# CORE_CM2 register map
Vendor: Texas Instruments
Peripheral module from a debugger description file (folder omap4460).
Registers are 32-bit, access not given, reset 0x30001 unless marked. A register's access mark holds for its fields unless they carry their own. Offsets are as the file gives them; lines under a group give offsets from that group; [hi:lo] are bit positions; {n}, {i} and the like mark numbered series; 'fields as' and 'values as' point back to an identical list; <NAME> marks a mode.

## CORE_CM2
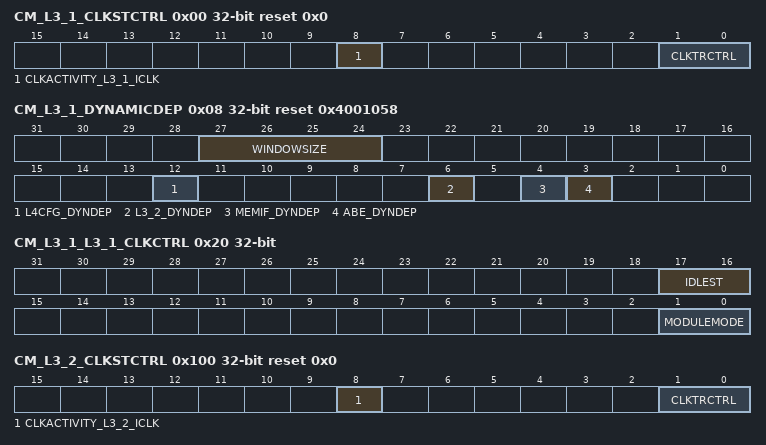
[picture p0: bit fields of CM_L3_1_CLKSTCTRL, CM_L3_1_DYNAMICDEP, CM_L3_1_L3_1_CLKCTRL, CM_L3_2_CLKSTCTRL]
0x00 CM_L3_1_CLKSTCTRL access per field reset 0x0 — This register enables the domain power state transition. It controls the hardware supervised domain power state transition between ON-ACTIVE and ON-INACTIVE states. It also holds 1 status bit per clock input of the domain.
  [8] CLKACTIVITY_L3_1_ICLK ro — This field indicates the state of the L3_1_ICLK clock in the domain. [warm reset insensitive]
    0=CLKACTIVITY_L3_1_ICLK_0_r (Corresponding clock is definitely gated); 1=CLKACTIVITY_L3_1_ICLK_1_r (Corresponding clock is running or gating/ungating transition is ongoing)
  [1:0] CLKTRCTRL rw — Controls the clock state transition of the L3_1 clock domain.
    0=NO_SLEEP: Sleep transition cannot be initiated. Wakeup transition may however occur.; 1=CLKTRCTRL_1_r (Reserved); 2=CLKTRCTRL_2_r (Reserved); 3=HW_AUTO: Automatic transition is enabled. Sleep and wakeup transition are based upon hardware conditions.
0x08 CM_L3_1_DYNAMICDEP reset 0x4001058 — This register controls the dynamic domain depedencies from L3_1 domain towards 'target' domains. It is relevant only for domain having INTRCONN master port(s).
  [27:24] WINDOWSIZE rw — Size of sliding window used to monitor INTRCONN interface activity for determination of auto-sleep feature. Time unit defined byCM_DYN_DEP_PRESCAL register.
  [12] L4CFG_DYNDEP — Dynamic dependency towards L4CFG clock domain (access R Rreturns1s)
    1=L4CFG_DYNDEP_1_r (Dependency is enabled)
  [6] L3_2_DYNDEP — Dynamic dependency towards L3_2 clock domain (access R Rreturns1s)
    1=L3_2_DYNDEP_1_r (Dependency is enabled)
  [4] MEMIF_DYNDEP — Dynamic dependency towards MEMIF clock domain (access R Rreturns1s)
    1=MEMIF_DYNDEP_1_r (Dependency is enabled)
  [3] ABE_DYNDEP — Dynamic dependency towards ABE clock domain (access R Rreturns1s)
    1=ABE_DYNDEP_1_r (Dependency is enabled)
0x20 CM_L3_1_L3_1_CLKCTRL — This register manages the L3_1 clocks.
  [17:16] IDLEST ro — Module idle status. [warm reset insensitive]
    0=IDLEST_0_r (Module is fully functional, including INTRCONN); 1=IDLEST_1_r (Module is performing transition: wakeup, or sleep, or sleep abortion); 2=IDLEST_2_r (Module is in idle mode (only INTRCONN part). It is functional if using separate functional clock); 3=IDLEST_3_r (Module is disabled and cannot be accessed)
  [1:0] MODULEMODE — Control the way mandatory clocks are managed. (access R Rreturns)
    1=MODULEMODE_1_r (Module is managed automatically by hardware according to clock domain transition. A clock domain sleep transition put module into idle. A wakeup domain transition put it back into function. If CLKTRCTRL=3, any INTRCONN access to module is always granted. Module clocks may be gated according to the clock domain state.)
0x100 CM_L3_2_CLKSTCTRL access per field reset 0x0 — This register enables the domain power state transition. It controls the hardware supervised domain power state transition between ON-ACTIVE and ON-INACTIVE states. It also holds 1 status bit per clock input of the domain.
  [8] CLKACTIVITY_L3_2_ICLK ro — This field indicates the state of the L3_2_ICLK clock in the domain. [warm reset insensitive]
    0=CLKACTIVITY_L3_2_ICLK_0_r (Corresponding clock is definitely gated); 1=CLKACTIVITY_L3_2_ICLK_1_r (Corresponding clock is running or gating/ungating transition is ongoing)
  [1:0] CLKTRCTRL rw — Controls the clock state transition of the L3_2 clock domain.
    values as CM_L3_1_CLKSTCTRL.CLKTRCTRL
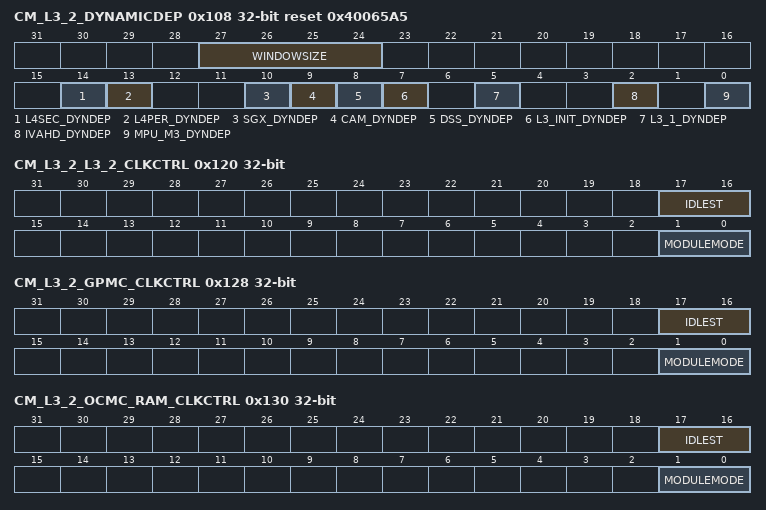
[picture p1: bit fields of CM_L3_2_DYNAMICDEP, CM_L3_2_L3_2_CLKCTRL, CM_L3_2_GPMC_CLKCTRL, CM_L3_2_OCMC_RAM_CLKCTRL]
0x108 CM_L3_2_DYNAMICDEP reset 0x40065A5 — This register controls the dynamic domain dependencies from L3_2 domain towards 'target' domains. It is relevant only for domain having INTERCONN master port(s).
  [27:24] WINDOWSIZE rw — Size of sliding window used to monitor INTRCONN interface activity for determination of auto-sleep feature. Time unit defined byCM_DYN_DEP_PRESCAL register.
  [14] L4SEC_DYNDEP ro — Dynamic dependency towards L4SEC clock domain
    1=L4SEC_DYNDEP_1_r (Dependency is enabled)
  [13] L4PER_DYNDEP — Dynamic dependency towards L4PER clock domain (access R Rreturns1s)
    1=L4PER_DYNDEP_1_r (Dependency is enabled)
  [10] SGX_DYNDEP — Dynamic dependency towards SGX clock domain (access R Rreturns1s)
    1=SGX_DYNDEP_1_r (Dependency is enabled)
  [9] CAM_DYNDEP ro — Dynamic dependency towards ISS clock domain
    0=CAM_DYNDEP_0_r (Dependency is disabled)
  [8] DSS_DYNDEP — Dynamic dependency towards DSS clock domain (access R Rreturns1s)
    1=DSS_DYNDEP_1_r (Dependency is enabled)
  [7] L3_INIT_DYNDEP — Dynamic dependency towards L3INIT clock domain (access R Rreturns1s)
    1=L3_INIT_DYNDEP_1_r (Dependency is enabled)
  [5] L3_1_DYNDEP — Dynamic dependency towards L3_1 clock domain (access R Rreturns1s)
    1=L3_1_DYNDEP_1_r (Dependency is enabled)
  [2] IVAHD_DYNDEP — Dynamic dependency towards IVAHD clock domain (access R Rreturns1s)
    1=IVAHD_DYNDEP_1_r (Dependency is enabled)
  [0] MPU_M3_DYNDEP — Dynamic dependency towards CORTEXM3 clock domain (access R Rreturns1s)
    1=MPU_M3_DYNDEP_1_r (Dependency is enabled)
0x120 CM_L3_2_L3_2_CLKCTRL — This register manages the L3_2 clocks.
  fields as CM_L3_1_L3_1_CLKCTRL
0x128 CM_L3_2_GPMC_CLKCTRL access per field — This register manages the GPMC clocks.
  [17:16] IDLEST ro — Module idle status. [warm reset insensitive]
    values as CM_L3_1_L3_1_CLKCTRL.IDLEST
  [1:0] MODULEMODE rw — Control the way mandatory clocks are managed.
    0=Module is temporarily disabled by software. Interconnect access to module are stalled. Can be used to change timing parameter of GPMC module.; 1=Module is managed automatically by hardware according to clock domain transition. A clock domain sleep transition put module into idle. A wakeup domain transition put it back into function. If CLKTRCTRL=3, any INTRCONN access to module is always granted. Module clocks may be gated according to the clock domain state.; 2=MODULEMODE_2_r (Reserved); 3=MODULEMODE_3_r (Reserved)
0x130 CM_L3_2_OCMC_RAM_CLKCTRL — This register manages the OCMC_RAM clocks.
  fields as CM_L3_1_L3_1_CLKCTRL
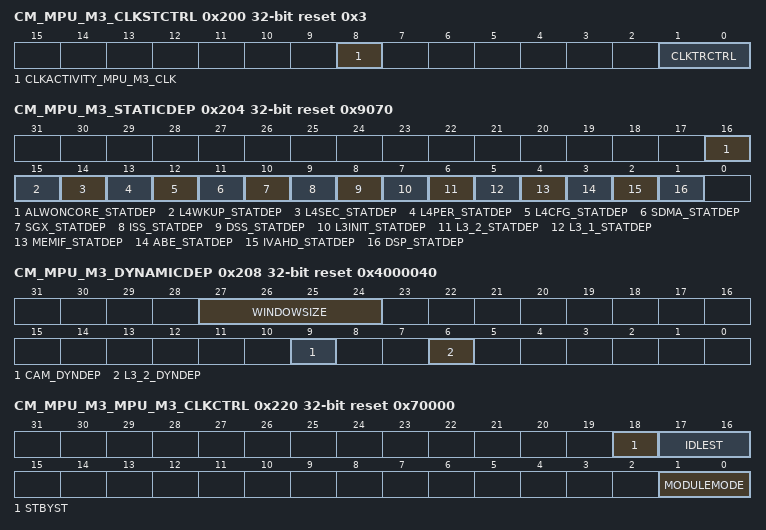
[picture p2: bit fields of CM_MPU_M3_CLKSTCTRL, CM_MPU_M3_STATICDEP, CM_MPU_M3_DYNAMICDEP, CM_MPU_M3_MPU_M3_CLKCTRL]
0x200 CM_MPU_M3_CLKSTCTRL access per field reset 0x3 — This register enables the domain power state transition. It controls the hardware supervised domain power state transition between ON-ACTIVE and ON-INACTIVE states. It also holds 1 status bit per clock input of the domain.
  [8] CLKACTIVITY_MPU_M3_CLK ro — This field indicates the state of the MPU_M3_CLK clock in the domain. [warm reset insensitive]
    0=CLKACTIVITY_MPU_M3_CLK_0_r (Corresponding clock is definitely gated); 1=CLKACTIVITY_MPU_M3_CLK_1_r (Corresponding clock is running or gating/ungating transition is ongoing)
  [1:0] CLKTRCTRL rw — Controls the clock state transition of the MPU_A3 clock domain.
    0=NO_SLEEP: Sleep transition cannot be initiated. Wakeup transition may however occur.; 1=SW_SLEEP: Start a software forced sleep transition on the domain; 2=SW_WKUP: Start a software forced wake-up transition on the domain; 3=HW_AUTO: Automatic transition is enabled. Sleep and wakeup transition are based upon hardware conditions.
0x204 CM_MPU_M3_STATICDEP access per field reset 0x9070 — This register controls the static domain dependencies from MPU_M3 domain towards 'target' domains. It is relevant only for domain having system initiator(s).
  [16] ALWONCORE_STATDEP ro — Static dependency towards ALWONCORE clock domain
    0=ALWONCORE_STATDEP_0_r (Dependency is disabled)
  [15] L4WKUP_STATDEP rw — Static dependency towards L4WKUP clock domain
    0=Dependency is disabled; 1=Dependency is enabled
  [14] L4SEC_STATDEP rw — Static dependency towards L4SEC clock domain
    0=Dependency is disabled; 1=Dependency is enabled
  [13] L4PER_STATDEP rw — Static dependency towards L4PER clock domain
    0=Dependency is disabled; 1=Dependency is enabled
  [12] L4CFG_STATDEP rw — Static dependency towards L4CFG clock domain
    0=Dependency is disabled; 1=Dependency is enabled
  [11] SDMA_STATDEP ro — Static dependency towards SDMA clock domain
    0=SDMA_STATDEP_0_r (Dependency is disabled)
  [10] SGX_STATDEP rw — Static dependency towards SGX clock domain
    0=Dependency is disabled; 1=Dependency is enabled
  [9] ISS_STATDEP ro — Static dependency towards ISS clock domain
    0=ISS_STATDEP_0_r (Dependency is disabled)
  [8] DSS_STATDEP rw — Static dependency towards DSS clock domain
    0=Dependency is disabled; 1=Dependency is enabled
  [7] L3INIT_STATDEP rw — Static dependency towards L3INIT clock domain
    0=Dependency is disabled; 1=Dependency is enabled
  [6] L3_2_STATDEP rw — Static dependency towards L3_2 clock domain
    0=Dependency is disabled; 1=Dependency is enabled
  [5] L3_1_STATDEP rw — Static dependency towards L3_1 clock domain
    0=Dependency is disabled; 1=Dependency is enabled
  [4] MEMIF_STATDEP rw — Static dependency towards MEMIF clock domain
    0=Dependency is disabled; 1=Dependency is enabled
  [3] ABE_STATDEP rw — Static dependency towards ABE clock domain
    0=Dependency is disabled; 1=Dependency is enabled
  [2] IVAHD_STATDEP rw — Static dependency towards IVAHD clock domain
    0=Dependency is disabled; 1=Dependency is enabled
  [1] DSP_STATDEP rw — Static dependency towards DSP clock domain
    0=Dependency is disabled; 1=Dependency is enabled
0x208 CM_MPU_M3_DYNAMICDEP reset 0x4000040 — This register controls the dynamic domain depedencies from MPU_A3 domain towards 'target' domains. It is relevant only for domain having INTRCONN master port(s).
  [27:24] WINDOWSIZE rw — Size of sliding window used to monitor INTRCONN interface activity for determination of auto-sleep feature. Time unit defined byCM_DYN_DEP_PRESCAL register.
  [9] CAM_DYNDEP ro — Dynamic dependency towards ISS clock domain
    0=CAM_DYNDEP_0_r (Dependency is disabled)
  [6] L3_2_DYNDEP — Dynamic dependency towards L3_2 clock domain (access R Rreturns1s)
    1=L3_2_DYNDEP_1_r (Dependency is enabled)
0x220 CM_MPU_M3_MPU_M3_CLKCTRL access per field reset 0x70000 — This register manages the MPU_A3 clocks.
  [18] STBYST ro — Module standby status. [warm reset insensitive]
    0=STBYST_0_r (Module is functional (not in standby)); 1=STBYST_1_r (Module is in standby)
  [17:16] IDLEST ro — Module idle status. [warm reset insensitive]
    values as CM_L3_1_L3_1_CLKCTRL.IDLEST
  [1:0] MODULEMODE rw — Control the way mandatory clocks are managed.
    0=Module is disable by software. Any INTRCONN access to module results in an error, except if resulting from a module wakeup (asynchronous wakeup).; 1=Module is managed automatically by hardware according to clock domain transition. A clock domain sleep transition put module into idle. A wakeup domain transition put it back into function. If CLKTRCTRL=3, any INTRCONN access to module is always granted. Module clocks may be gated according to the clock domain state.; 2=MODULEMODE_2_r (Reserved); 3=MODULEMODE_3_r (Reserved)
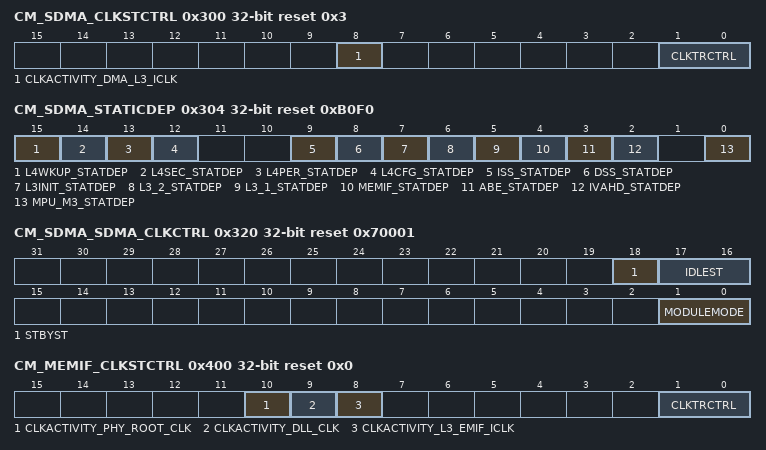
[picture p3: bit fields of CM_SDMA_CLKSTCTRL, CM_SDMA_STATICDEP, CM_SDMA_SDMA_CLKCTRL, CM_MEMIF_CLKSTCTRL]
0x300 CM_SDMA_CLKSTCTRL access per field reset 0x3 — This register enables the domain power state transition. It controls the hardware supervised domain power state transition between ON-ACTIVE and ON-INACTIVE states. It also holds 1 status bit per clock input of the domain.
  [8] CLKACTIVITY_DMA_L3_ICLK ro — This field indicates the state of the DMA_L3_ICLK clock in the domain. [warm reset insensitive]
    0=CLKACTIVITY_DMA_L3_ICLK_0_r (Corresponding clock is definitely gated); 1=CLKACTIVITY_DMA_L3_ICLK_1_r (Corresponding clock is running or gating/ungating transition is ongoing)
  [1:0] CLKTRCTRL rw — Controls the clock state transition of the SDMA clock domain.
    0=NO_SLEEP: Sleep transition cannot be initiated. Wakeup transition may however occur.; 1=CLKTRCTRL_1_r (Reserved); 2=SW_WKUP: Start a software forced wake-up transition on the domain; 3=HW_AUTO: Automatic transition is enabled. Sleep and wakeup transition are based upon hardware conditions.
0x304 CM_SDMA_STATICDEP reset 0xB0F0 — This register controls the static domain dependencies from SDMA domain towards 'target' domains. It is relevant only for domain having system initiator(s).
  [15] L4WKUP_STATDEP rw — Static dependency towards L4WKUP clock domain
    0=Dependency is disabled; 1=Dependency is enabled
  [14] L4SEC_STATDEP rw — Static dependency towards L4SEC clock domain
    0=Dependency is disabled; 1=Dependency is enabled
  [13] L4PER_STATDEP rw — Static dependency towards L4PER clock domain
    0=Dependency is disabled; 1=Dependency is enabled
  [12] L4CFG_STATDEP rw — Static dependency towards L4CFG clock domain
    0=Dependency is disabled; 1=Dependency is enabled
  [9] ISS_STATDEP ro — Static dependency towards ISS clock domain
    0=ISS_STATDEP_0_r (Dependency is disabled)
  [8] DSS_STATDEP rw — Static dependency towards DSS clock domain
    0=Dependency is disabled; 1=Dependency is enabled
  [7] L3INIT_STATDEP rw — Static dependency towards L3INIT clock domain
    0=Dependency is disabled; 1=Dependency is enabled
  [6] L3_2_STATDEP — Static dependency towards L3_2 clock domain (access R Rreturns1s)
    1=L3_2_STATDEP_1_r (Dependency is enabled)
  [5] L3_1_STATDEP rw — Static dependency towards L3_1 clock domain
    0=Dependency is disabled; 1=Dependency is enabled
  [4] MEMIF_STATDEP rw — Static dependency towards MEMIF clock domain
    0=Dependency is disabled; 1=Dependency is enabled
  [3] ABE_STATDEP rw — Static dependency towards ABE clock domain
    0=Dependency is disabled; 1=Dependency is enabled
  [2] IVAHD_STATDEP rw — Static dependency towards IVAHD clock domain
    0=Dependency is disabled; 1=Dependency is enabled
  [0] MPU_M3_STATDEP rw — Static dependency towards MPU_A3 clock domain
    0=Dependency is disabled; 1=Dependency is enabled
0x308 CM_SDMA_DYNAMICDEP ro reset 0x0 — This register controls the dynamic domain depedencies from SDMA domain towards 'target' domains. It is relevant only for domain having INTRCONN master port(s).
  [6] L3_2_DYNDEP — Dynamic dependency towards L3_2 clock domain
    0=L3_2_DYNDEP_0_r (Dependency is disabled)
0x320 CM_SDMA_SDMA_CLKCTRL reset 0x70001 — This register manages the SDMA clocks.
  [18] STBYST ro — Module standby status. [warm reset insensitive]
    values as CM_MPU_M3_MPU_M3_CLKCTRL.STBYST
  [17:16] IDLEST ro — Module idle status. [warm reset insensitive]
    values as CM_L3_1_L3_1_CLKCTRL.IDLEST
  [1:0] MODULEMODE — Control the way mandatory clocks are managed. (access R Rreturns)
    values as CM_L3_1_L3_1_CLKCTRL.MODULEMODE
0x400 CM_MEMIF_CLKSTCTRL access per field reset 0x0 — This register enables the domain power state transition. It controls the hardware supervised domain power state transition between ON-ACTIVE and ON-INACTIVE states. It also holds 1 status bit per clock input of the domain.
  [10] CLKACTIVITY_PHY_ROOT_CLK ro — This field indicates the state of the PHY_ROOT_CLK clock in the domain. [warm reset insensitive]
    0=CLKACTIVITY_PHY_ROOT_CLK_0_r (Corresponding clock is definitely gated); 1=CLKACTIVITY_PHY_ROOT_CLK_1_r (Corresponding clock is running or gating/ungating transition is ongoing)
  [9] CLKACTIVITY_DLL_CLK ro — This field indicates the state of the DLL_CLK clock in the domain. [warm reset insensitive]
    0=CLKACTIVITY_DLL_CLK_0_r (Corresponding clock is definitely gated); 1=CLKACTIVITY_DLL_CLK_1_r (Corresponding clock is running or gating/ungating transition is ongoing)
  [8] CLKACTIVITY_L3_EMIF_ICLK ro — This field indicates the state of the L3_EMIF_ICLK clock in the domain. [warm reset insensitive]
    0=CLKACTIVITY_L3_EMIF_ICLK_0_r (Corresponding clock is definitely gated); 1=CLKACTIVITY_L3_EMIF_ICLK_1_r (Corresponding clock is running or gating/ungating transition is ongoing)
  [1:0] CLKTRCTRL rw — Controls the clock state transition of the MEMIF clock domain.
    values as CM_SDMA_CLKSTCTRL.CLKTRCTRL
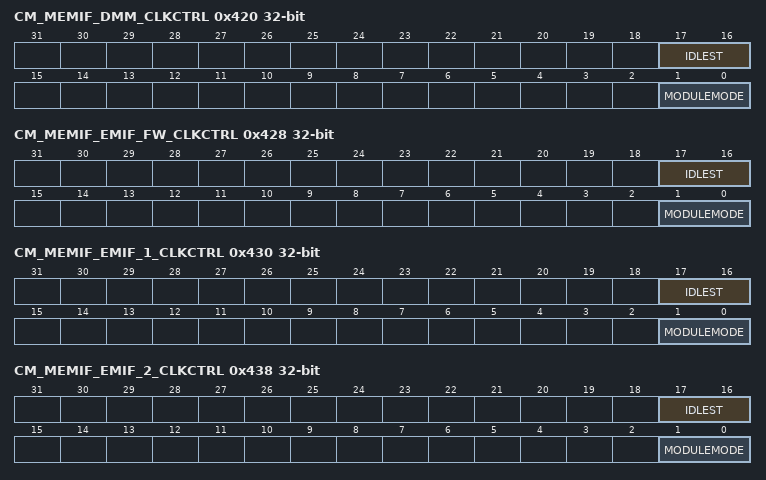
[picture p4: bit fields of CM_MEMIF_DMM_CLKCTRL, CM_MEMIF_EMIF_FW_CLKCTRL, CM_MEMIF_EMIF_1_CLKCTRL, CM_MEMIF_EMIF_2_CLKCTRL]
0x420 CM_MEMIF_DMM_CLKCTRL — This register manages the DMM clocks.
  fields as CM_L3_1_L3_1_CLKCTRL
0x428 CM_MEMIF_EMIF_FW_CLKCTRL — This register manages the EMIF_FW clocks.
  fields as CM_L3_1_L3_1_CLKCTRL
0x430 CM_MEMIF_EMIF_1_CLKCTRL access per field — This register manages the EMIF_1 clocks.
  [17:16] IDLEST ro — Module idle status. [warm reset insensitive]
    values as CM_L3_1_L3_1_CLKCTRL.IDLEST
  [1:0] MODULEMODE rw — Control the way mandatory clocks are managed.
    0=Module is temporarily disabled by software. Interconnect access to module are stalled. Can be used to change timing parameter of EMIF1 module.; 1=Module is managed automatically by hardware according to clock domain transition. A clock domain sleep transition put module into idle. A wakeup domain transition put it back into function. If CLKTRCTRL=3, any INTRCONN access to module is always granted. Module clocks may be gated according to the clock domain state.; 2=MODULEMODE_2_r (Reserved); 3=MODULEMODE_3_r (Reserved)
0x438 CM_MEMIF_EMIF_2_CLKCTRL access per field — This register manages the EMIF_2 clocks.
  [17:16] IDLEST ro — Module idle status. [warm reset insensitive]
    values as CM_L3_1_L3_1_CLKCTRL.IDLEST
  [1:0] MODULEMODE rw — Control the way mandatory clocks are managed.
    0=Module is temporarily disabled by software. Interconnect access to module are stalled. Can be used to change timing parameter of EMIF2 module.; 1=Module is managed automatically by hardware according to clock domain transition. A clock domain sleep transition put module into idle. A wakeup domain transition put it back into function. If CLKTRCTRL=3, any INTRCONN access to module is always granted. Module clocks may be gated according to the clock domain state.; 2=MODULEMODE_2_r (Reserved); 3=MODULEMODE_3_r (Reserved)
0x440 CM_MEMIF_DLL_CLKCTRL access per field reset 0x0 — This register manages the DLL clock.
  [8] OPTFCLKEN_DLL_CLK rw — Optional functional clock control.
    0=Optional functional clock is disabled. DLL_CLK can be gated when MEMIF domain performs sleep transition; 1=Optional functional clock is enabled. DLL_CLK is garantied to not be gated if already running.
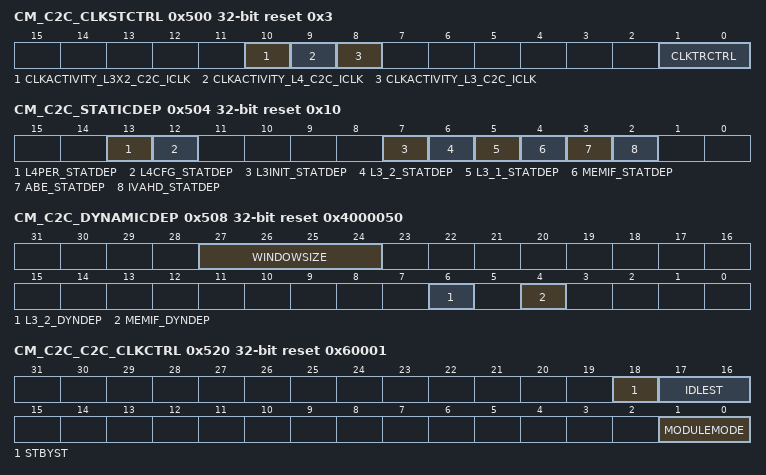
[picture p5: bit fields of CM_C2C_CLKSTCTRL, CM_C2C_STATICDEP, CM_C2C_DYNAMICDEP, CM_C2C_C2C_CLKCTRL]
0x500 CM_C2C_CLKSTCTRL access per field reset 0x3 — This register enables the domain power state transition. It controls the hardware supervised domain power state transition between ON-ACTIVE and ON-INACTIVE states. It also holds 1 status bit per clock input of the domain.
  [10] CLKACTIVITY_L3X2_C2C_ICLK ro — This field indicates the state of the C2C_L3X2_ICLK clock in the domain. [warm reset insensitive]
    0=CLKACTIVITY_L3X2_C2C_ICLK_0_r (Corresponding clock is definitely gated); 1=CLKACTIVITY_L3X2_C2C_ICLK_1_r (Corresponding clock is running or gating/ungating transition is ongoing)
  [9] CLKACTIVITY_L4_C2C_ICLK ro — This field indicates the state of the L4_C2C_ICLK clock in the domain. [warm reset insensitive]
    0=CLKACTIVITY_L4_C2C_ICLK_0_r (Corresponding clock is definitely gated); 1=CLKACTIVITY_L4_C2C_ICLK_1_r (Corresponding clock is running or gating/ungating transition is ongoing)
  [8] CLKACTIVITY_L3_C2C_ICLK ro — This field indicates the state of the L3_C2C_ICLK clock in the domain. [warm reset insensitive]
    0=CLKACTIVITY_L3_C2C_ICLK_0_r (Corresponding clock is definitely gated); 1=CLKACTIVITY_L3_C2C_ICLK_1_r (Corresponding clock is running or gating/ungating transition is ongoing)
  [1:0] CLKTRCTRL rw — Controls the clock state transition of the C2C clock domain.
    values as CM_SDMA_CLKSTCTRL.CLKTRCTRL
0x504 CM_C2C_STATICDEP access per field reset 0x10 — This register controls the static domain depedencies from C2C domain towards 'target' domains. It is relevant only for domain having system initiator(s).
  [all] fields
    0=Dependency is disabled; 1=Dependency is enabled
  [13] L4PER_STATDEP rw — Static dependency towards L4PER clock domain
  [12] L4CFG_STATDEP rw — Static dependency towards L4CFG clock domain
  [7] L3INIT_STATDEP rw — Static dependency towards L3INIT clock domain
  [6] L3_2_STATDEP rw — Static dependency towards L3_2 clock domain
  [5] L3_1_STATDEP rw — Static dependency towards L3_1 clock domain
  [4] MEMIF_STATDEP rw — Static dependency towards MEMIF clock domain
  [3] ABE_STATDEP rw — Static dependency towards ABE clock domain
  [2] IVAHD_STATDEP rw — Static dependency towards IVAHD clock domain
0x508 CM_C2C_DYNAMICDEP reset 0x4000050 — This register controls the dynamic domain depedencies from C2C domain towards 'target' domains. It is relevant only for domain having INTRCONN master port(s).
  [27:24] WINDOWSIZE rw — Size of sliding window used to monitor INTRCONN interface activity for determination of auto-sleep feature. Time unit defined byCM_DYN_DEP_PRESCAL register.
  [6] L3_2_DYNDEP — Dynamic dependency towards L3_2 clock domain (access R Rreturns1s)
    1=L3_2_DYNDEP_1_r (Dependency is enabled)
  [4] MEMIF_DYNDEP — Dynamic dependency towards MEMIF clock domain (access R Rreturns1s)
    1=MEMIF_DYNDEP_1_r (Dependency is enabled)
0x520 CM_C2C_C2C_CLKCTRL reset 0x60001 — This register manages the C2C clocks.
  [18] STBYST ro — C2C module standby status. [warm reset insensitive]
    values as CM_MPU_M3_MPU_M3_CLKCTRL.STBYST
  [17:16] IDLEST ro — C2C interface idle status. [warm reset insensitive]
    0=IDLEST_0_r (C2C interface is in functional state); 1=IDLEST_1_r (C2C interface is in a transitory state); 2=IDLEST_2_r (C2C interface is in IDLE state)
  [1:0] MODULEMODE — Control the way mandatory clocks are managed. (access R Rreturns)
    values as CM_L3_1_L3_1_CLKCTRL.MODULEMODE
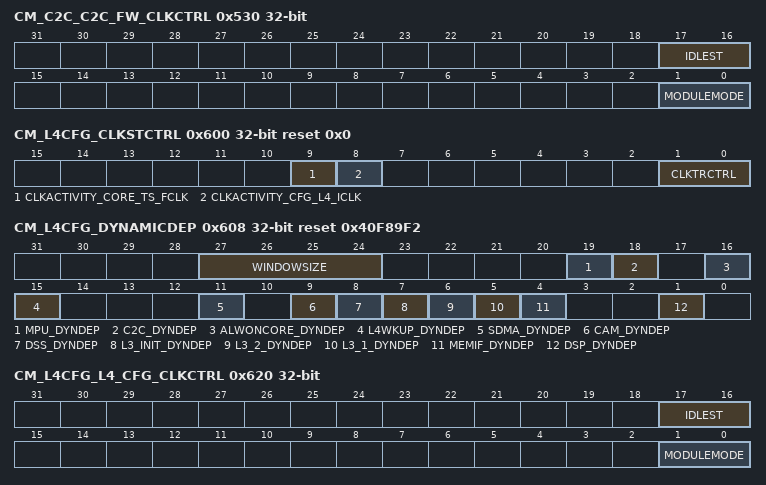
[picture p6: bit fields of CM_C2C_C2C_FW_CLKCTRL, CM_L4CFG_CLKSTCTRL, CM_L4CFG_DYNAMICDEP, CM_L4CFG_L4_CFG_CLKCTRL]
0x530 CM_C2C_C2C_FW_CLKCTRL — This register manages the C2C_FW clocks.
  fields as CM_L3_1_L3_1_CLKCTRL
0x600 CM_L4CFG_CLKSTCTRL access per field reset 0x0 — This register enables the domain power state transition. It controls the hardware supervised domain power state transition between ON-ACTIVE and ON-INACTIVE states. It also holds 1 status bit per clock input of the domain.
  [9] CLKACTIVITY_CORE_TS_FCLK ro — This field indicates the state of the CORE_TS_FCLK clock in the domain. [warm reset insensitive]
    0=CLKACTIVITY_CORE_TS_FCLK_0_r (Corresponding clock is definitely gated); 1=CLKACTIVITY_CORE_TS_FCLK_1_r (Corresponding clock is running or gating/ungating transition is on-going)
  [8] CLKACTIVITY_CFG_L4_ICLK ro — This field indicates the state of the CFG_L4_ICLK clock in the domain. [warm reset insensitive]
    0=CLKACTIVITY_CFG_L4_ICLK_0_r (Corresponding clock is gated.); 1=CLKACTIVITY_CFG_L4_ICLK_1_r (Corresponding clock is running or gating/ungating; transition is ongoing.)
  [1:0] CLKTRCTRL rw — Controls the clock state transition of the L4CFG clock domain.
    values as CM_L3_1_CLKSTCTRL.CLKTRCTRL
0x608 CM_L4CFG_DYNAMICDEP reset 0x40F89F2 — This register controls the dynamic domain depedencies from L4_CFG domain towards 'target' domains. It is relevant only for domain having INTRCONN master port(s).
  [27:24] WINDOWSIZE rw — Size of sliding window used to monitor INTRCONN interface activity for determination of auto-sleep feature. Time unit defined byCM_DYN_DEP_PRESCAL register.
  [19] MPU_DYNDEP — Dynamic dependency towards MPU clock domain (access R Rretunrs1s)
    1=MPU_DYNDEP_1_r (Dependency is enabled)
  [18] C2C_DYNDEP — Dynamic dependency towards C2C clock domain (access R Rreturns1s)
    1=C2C_DYNDEP_1_r (Dependency is enabled)
  [16] ALWONCORE_DYNDEP — Dynamic dependency towards ALWONCORE clock domain (access R Rreturns1s)
    1=ALWONCORE_DYNDEP_1_r (Dependency is enabled)
  [15] L4WKUP_DYNDEP — Dynamic dependency towards L4WKUP clock domain (access R Rreturns1s)
    1=L4WKUP_DYNDEP_1_r (Dependency is enabled)
  [11] SDMA_DYNDEP — Dynamic dependency towards SDMA clock domain (access R Rreturns1s)
    1=SDMA_DYNDEP_1_r (Dependency is enabled)
  [9] CAM_DYNDEP ro — Dynamic dependency towards ISS clock domain
    0=CAM_DYNDEP_0_r (Dependency is disabled)
  [8] DSS_DYNDEP — Dynamic dependency towards DSS clock domain (access R Rreturns1s)
    1=DSS_DYNDEP_1_r (Dependency is enabled)
  [7] L3_INIT_DYNDEP — Dynamic dependency towards L3INIT clock domain (access R Rreturns1s)
    1=L3_INIT_DYNDEP_1_r (Dependency is enabled)
  [6] L3_2_DYNDEP — Dynamic dependency towards L3_2 clock domain (access R Rreturns1s)
    1=L3_2_DYNDEP_1_r (Dependency is enabled)
  [5] L3_1_DYNDEP — Dynamic dependency towards L3_1 clock domain (access R Rreturns1s)
    1=L3_1_DYNDEP_1_r (Dependency is enabled)
  [4] MEMIF_DYNDEP — Dynamic dependency towards MEMIF clock domain (access R Rreturns1s)
    1=MEMIF_DYNDEP_1_r (Dependency is enabled)
  [1] DSP_DYNDEP — Dynamic dependency towards DSP clock domain (access R Rreturns1s)
    1=DSP_DYNDEP_1_r (Dependency is enabled)
0x620 CM_L4CFG_L4_CFG_CLKCTRL — This register manages the L4_CFG clocks.
  fields as CM_L3_1_L3_1_CLKCTRL
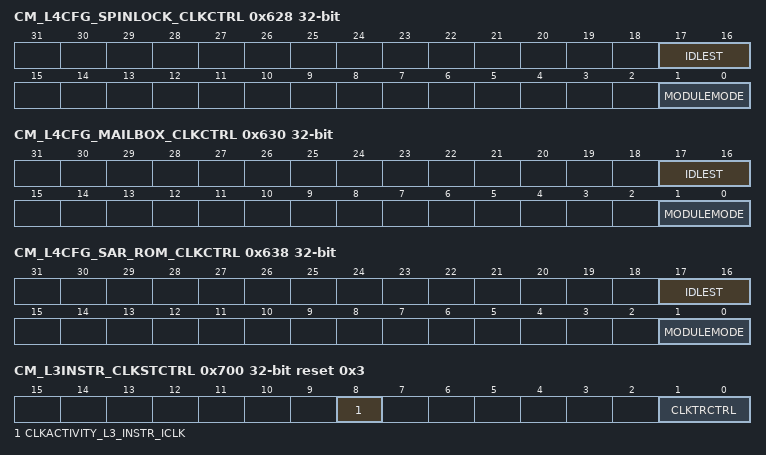
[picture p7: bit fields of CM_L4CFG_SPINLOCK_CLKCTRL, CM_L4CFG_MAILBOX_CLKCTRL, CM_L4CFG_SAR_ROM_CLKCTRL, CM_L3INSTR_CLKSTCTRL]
0x628 CM_L4CFG_SPINLOCK_CLKCTRL — This register manages the HW_SEM clocks.
  fields as CM_L3_1_L3_1_CLKCTRL
0x630 CM_L4CFG_MAILBOX_CLKCTRL — This register manages the MAILBOX clocks.
  fields as CM_L3_1_L3_1_CLKCTRL
0x638 CM_L4CFG_SAR_ROM_CLKCTRL — This register manages the SAR_ROM clocks.
  fields as CM_L3_1_L3_1_CLKCTRL
0x700 CM_L3INSTR_CLKSTCTRL reset 0x3 — This register enables the domain power state transition. It controls the hardware supervised domain power state transition between ON-ACTIVE and ON-INACTIVE states. It also holds 1 status bit per clock input of the domain.
  [8] CLKACTIVITY_L3_INSTR_ICLK ro — This field indicates the state of the L3_INSTR_GICLK clock in the domain. [warm reset insensitive]
    0=CLKACTIVITY_L3_INSTR_ICLK_0_r (Corresponding clock is definitely gated); 1=CLKACTIVITY_L3_INSTR_ICLK_1_r (Corresponding clock is running or gating/ungating transition is ongoing)
  [1:0] CLKTRCTRL — Controls the clock state transition of the L3INSTR clock domain. (access R Rreturns1s)
    3=CLKTRCTRL_3_r (HW_AUTO: Automatic transition is enabled. Sleep and wakeup transition are based upon hardware conditions.)
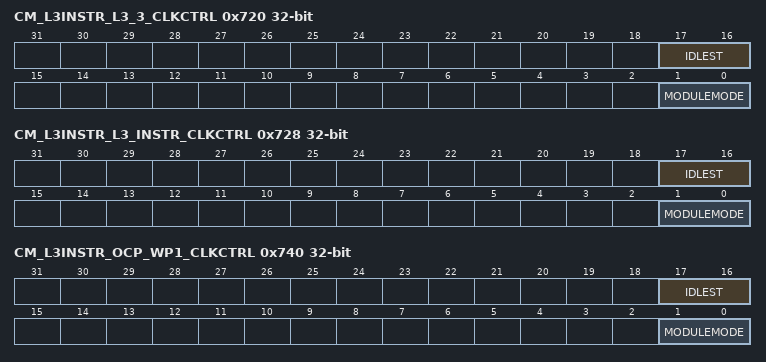
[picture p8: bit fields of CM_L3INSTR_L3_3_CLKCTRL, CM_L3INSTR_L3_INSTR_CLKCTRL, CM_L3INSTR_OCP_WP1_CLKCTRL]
0x720 CM_L3INSTR_L3_3_CLKCTRL access per field — This register manages the L3_3 clocks. [warm reset insensitive]
  [17:16] IDLEST ro — Module idle status.
    values as CM_L3_1_L3_1_CLKCTRL.IDLEST
  [1:0] MODULEMODE rw — Control the way mandatory clocks are managed.
    values as CM_MPU_M3_MPU_M3_CLKCTRL.MODULEMODE
0x728 CM_L3INSTR_L3_INSTR_CLKCTRL access per field — This register manages the L3 INSTRUMENTATION clocks. [warm reset insensitive]
  fields as CM_L3INSTR_L3_3_CLKCTRL
0x740 CM_L3INSTR_OCP_WP1_CLKCTRL access per field — This register manages the OCP_WP1 clocks. [warm reset insensitive]
  [17:16] IDLEST ro — Module idle status.
    3=IDLEST_3_r (Module is disabled and cannot be accessed); 2=IDLEST_2_r (Module is in idle mode (only Interconnect part). It is functional if using separate functional clock); 1=IDLEST_1_r (Module is performing transition: wakeup, or sleep, or sleep abortion); 0=IDLEST_0_r (Module is fully functional, including Interconnect)
  [1:0] MODULEMODE rw — Control the way mandatory clocks are managed.
    0=Module is disable by software. Any Interconnect access to module results in an error, except if resulting from a module wakeup (asynchronous wakeup).; 1=Module is managed automatically by hardware according to clock domain transition. A clock domain sleep transition put module into idle. A wakeup domain transition put it back into function. If CLKTRCTRL=3, any Interconnect access to module is always granted. Module clocks may be gated according to the clock domain state.; 2=MODULEMODE_2_r (Reserved); 3=MODULEMODE_3_r (Reserved)
